# ESP32-S3 register map
Vendor: ESPRESSIF SYSTEMS (SHANGHAI) CO., LTD.; Series: ESP32 S-Series; File version: 22
CPU: Xtensa LX7 r0p0, little endian, no MPU, FPU, 0 interrupt priority bits
Address unit: 32 bits
Registers are 32-bit, read-write, reset 0x0 unless marked. A register's access mark holds for its fields unless they carry their own. Offsets are from the block's base; [hi:lo] are bit positions; {n}, {i} and the like mark numbered series.

## USB_DEVICE — Full-speed USB Serial/JTAG Controller
Base 0x60038000
0x00 EP1 — Endpoint 1 FIFO register
  [7:0] RDWR_BYTE — Write and read byte data to/from UART Tx/Rx FIFO through this field. When USB_DEVICE_SERIAL_IN_EMPTY_INT is set, then user can write data (up to 64 bytes) into UART Tx FIFO. When USB_DEVICE_SERIAL_OUT_RECV_PKT_INT is set, user can check USB_DEVICE_OUT_EP1_WR_ADDR USB_DEVICE_OUT_EP0_RD_ADDR to know how many data is received, then read data from UART Rx FIFO.
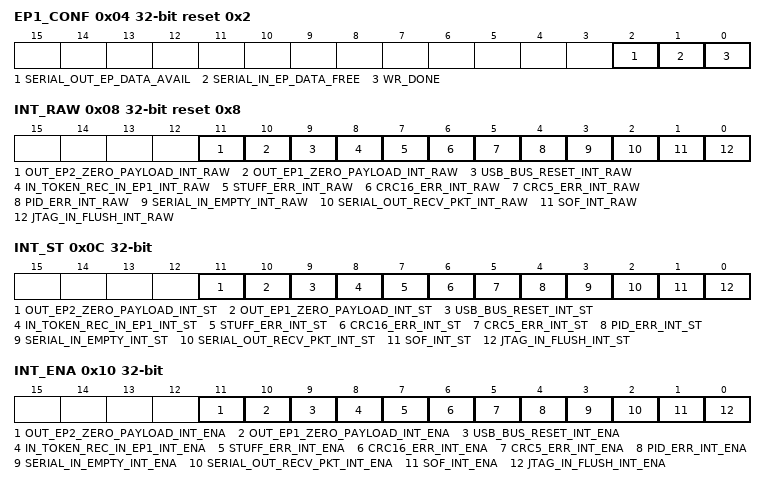
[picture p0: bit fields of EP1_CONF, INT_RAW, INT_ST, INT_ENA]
0x04 EP1_CONF access per field reset 0x2 — Endpoint 1 configure and status register
  [2] SERIAL_OUT_EP_DATA_AVAIL ro — 1'b1: Indicate there is data in UART Rx FIFO.
  [1] SERIAL_IN_EP_DATA_FREE ro — 1'b1: Indicate UART Tx FIFO is not full and can write data into in. After writing USB_DEVICE_WR_DONE, this bit would be 0 until data in UART Tx FIFO is read by USB Host.
  [0] WR_DONE wo — Set this bit to indicate writing byte data to UART Tx FIFO is done.
0x08 INT_RAW reset 0x8 — Raw status interrupt
  [11] OUT_EP2_ZERO_PAYLOAD_INT_RAW — The raw interrupt bit turns to high level when OUT endpoint 2 received packet with zero palyload.
  [10] OUT_EP1_ZERO_PAYLOAD_INT_RAW — The raw interrupt bit turns to high level when OUT endpoint 1 received packet with zero palyload.
  [9] USB_BUS_RESET_INT_RAW — The raw interrupt bit turns to high level when usb bus reset is detected.
  [8] IN_TOKEN_REC_IN_EP1_INT_RAW — The raw interrupt bit turns to high level when IN token for IN endpoint 1 is received.
  [7] STUFF_ERR_INT_RAW — The raw interrupt bit turns to high level when stuff error is detected.
  [6] CRC16_ERR_INT_RAW — The raw interrupt bit turns to high level when CRC16 error is detected.
  [5] CRC5_ERR_INT_RAW — The raw interrupt bit turns to high level when CRC5 error is detected.
  [4] PID_ERR_INT_RAW — The raw interrupt bit turns to high level when pid error is detected.
  [3] SERIAL_IN_EMPTY_INT_RAW — The raw interrupt bit turns to high level when Serial Port IN Endpoint is empty.
  [2] SERIAL_OUT_RECV_PKT_INT_RAW — The raw interrupt bit turns to high level when Serial Port OUT Endpoint received one packet.
  [1] SOF_INT_RAW — The raw interrupt bit turns to high level when SOF frame is received.
  [0] JTAG_IN_FLUSH_INT_RAW — The raw interrupt bit turns to high level when flush cmd is received for IN endpoint 2 of JTAG.
0x0C INT_ST ro — Masked interrupt
  [11] OUT_EP2_ZERO_PAYLOAD_INT_ST — The raw interrupt status bit for the USB_DEVICE_OUT_EP2_ZERO_PAYLOAD_INT interrupt.
  [10] OUT_EP1_ZERO_PAYLOAD_INT_ST — The raw interrupt status bit for the USB_DEVICE_OUT_EP1_ZERO_PAYLOAD_INT interrupt.
  [9] USB_BUS_RESET_INT_ST — The raw interrupt status bit for the USB_DEVICE_USB_BUS_RESET_INT interrupt.
  [8] IN_TOKEN_REC_IN_EP1_INT_ST — The raw interrupt status bit for the USB_DEVICE_IN_TOKEN_REC_IN_EP1_INT interrupt.
  [7] STUFF_ERR_INT_ST — The raw interrupt status bit for the USB_DEVICE_STUFF_ERR_INT interrupt.
  [6] CRC16_ERR_INT_ST — The raw interrupt status bit for the USB_DEVICE_CRC16_ERR_INT interrupt.
  [5] CRC5_ERR_INT_ST — The raw interrupt status bit for the USB_DEVICE_CRC5_ERR_INT interrupt.
  [4] PID_ERR_INT_ST — The raw interrupt status bit for the USB_DEVICE_PID_ERR_INT interrupt.
  [3] SERIAL_IN_EMPTY_INT_ST — The raw interrupt status bit for the USB_DEVICE_SERIAL_IN_EMPTY_INT interrupt.
  [2] SERIAL_OUT_RECV_PKT_INT_ST — The raw interrupt status bit for the USB_DEVICE_SERIAL_OUT_RECV_PKT_INT interrupt.
  [1] SOF_INT_ST — The raw interrupt status bit for the USB_DEVICE_SOF_INT interrupt.
  [0] JTAG_IN_FLUSH_INT_ST — The raw interrupt status bit for the USB_DEVICE_JTAG_IN_FLUSH_INT interrupt.
0x10 INT_ENA — Interrupt enable bits
  [11] OUT_EP2_ZERO_PAYLOAD_INT_ENA — The interrupt enable bit for the USB_DEVICE_OUT_EP2_ZERO_PAYLOAD_INT interrupt.
  [10] OUT_EP1_ZERO_PAYLOAD_INT_ENA — The interrupt enable bit for the USB_DEVICE_OUT_EP1_ZERO_PAYLOAD_INT interrupt.
  [9] USB_BUS_RESET_INT_ENA — The interrupt enable bit for the USB_DEVICE_USB_BUS_RESET_INT interrupt.
  [8] IN_TOKEN_REC_IN_EP1_INT_ENA — The interrupt enable bit for the USB_DEVICE_IN_TOKEN_REC_IN_EP1_INT interrupt.
  [7] STUFF_ERR_INT_ENA — The interrupt enable bit for the USB_DEVICE_STUFF_ERR_INT interrupt.
  [6] CRC16_ERR_INT_ENA — The interrupt enable bit for the USB_DEVICE_CRC16_ERR_INT interrupt.
  [5] CRC5_ERR_INT_ENA — The interrupt enable bit for the USB_DEVICE_CRC5_ERR_INT interrupt.
  [4] PID_ERR_INT_ENA — The interrupt enable bit for the USB_DEVICE_PID_ERR_INT interrupt.
  [3] SERIAL_IN_EMPTY_INT_ENA — The interrupt enable bit for the USB_DEVICE_SERIAL_IN_EMPTY_INT interrupt.
  [2] SERIAL_OUT_RECV_PKT_INT_ENA — The interrupt enable bit for the USB_DEVICE_SERIAL_OUT_RECV_PKT_INT interrupt.
  [1] SOF_INT_ENA — The interrupt enable bit for the USB_DEVICE_SOF_INT interrupt.
  [0] JTAG_IN_FLUSH_INT_ENA — The interrupt enable bit for the USB_DEVICE_JTAG_IN_FLUSH_INT interrupt.
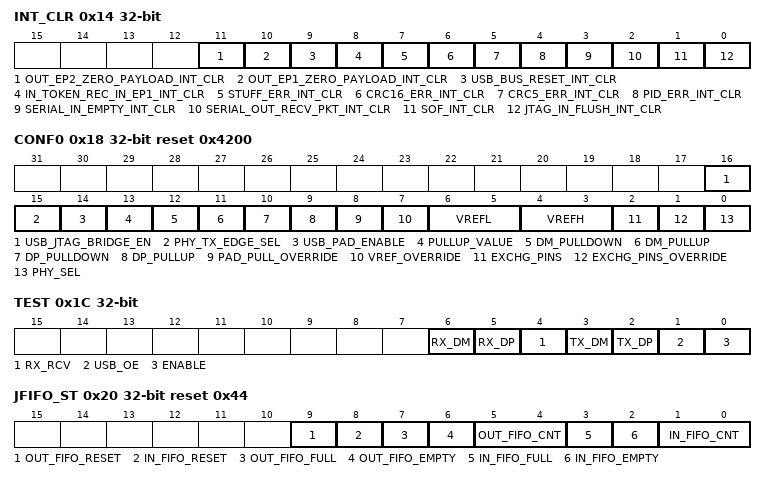
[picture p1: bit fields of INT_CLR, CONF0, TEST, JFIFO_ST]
0x14 INT_CLR wo — Interrupt clear bits
  [11] OUT_EP2_ZERO_PAYLOAD_INT_CLR — Set this bit to clear the USB_DEVICE_OUT_EP2_ZERO_PAYLOAD_INT interrupt.
  [10] OUT_EP1_ZERO_PAYLOAD_INT_CLR — Set this bit to clear the USB_DEVICE_OUT_EP1_ZERO_PAYLOAD_INT interrupt.
  [9] USB_BUS_RESET_INT_CLR — Set this bit to clear the USB_DEVICE_USB_BUS_RESET_INT interrupt.
  [8] IN_TOKEN_REC_IN_EP1_INT_CLR — Set this bit to clear the USB_DEVICE_IN_TOKEN_IN_EP1_INT interrupt.
  [7] STUFF_ERR_INT_CLR — Set this bit to clear the USB_DEVICE_STUFF_ERR_INT interrupt.
  [6] CRC16_ERR_INT_CLR — Set this bit to clear the USB_DEVICE_CRC16_ERR_INT interrupt.
  [5] CRC5_ERR_INT_CLR — Set this bit to clear the USB_DEVICE_CRC5_ERR_INT interrupt.
  [4] PID_ERR_INT_CLR — Set this bit to clear the USB_DEVICE_PID_ERR_INT interrupt.
  [3] SERIAL_IN_EMPTY_INT_CLR — Set this bit to clear the USB_DEVICE_SERIAL_IN_EMPTY_INT interrupt.
  [2] SERIAL_OUT_RECV_PKT_INT_CLR — Set this bit to clear the USB_DEVICE_SERIAL_OUT_RECV_PKT_INT interrupt.
  [1] SOF_INT_CLR — Set this bit to clear the USB_DEVICE_JTAG_SOF_INT interrupt.
  [0] JTAG_IN_FLUSH_INT_CLR — Set this bit to clear the USB_DEVICE_JTAG_IN_FLUSH_INT interrupt.
0x18 CONF0 reset 0x4200 — Configure 0 register
  [16] USB_JTAG_BRIDGE_EN — Set this bit usb_jtag, the connection between usb_jtag and internal JTAG is disconnected, and MTMS, MTDI, MTCK are output through GPIO Matrix, MTDO is input through GPIO Matrix.
  [15] PHY_TX_EDGE_SEL — 0: TX output at clock negedge. 1: Tx output at clock posedge.
  [14] USB_PAD_ENABLE — Enable USB pad function.
  [13] PULLUP_VALUE — Control pull up value.
  [12] DM_PULLDOWN — Control USB D- pull down.
  [11] DM_PULLUP — Control USB D- pull up.
  [10] DP_PULLDOWN — Control USB D+ pull down.
  [9] DP_PULLUP — Control USB D+ pull up.
  [8] PAD_PULL_OVERRIDE — Enable software control USB D+ D- pullup pulldown
  [7] VREF_OVERRIDE — Enable software control input threshold
  [6:5] VREFL — Control single-end input low threshold,0.8V to 1.04V, step 80mV
  [4:3] VREFH — Control single-end input high threshold,1.76V to 2V, step 80mV
  [2] EXCHG_PINS — USB D+ D- exchange
  [1] EXCHG_PINS_OVERRIDE — Enable software control USB D+ D- exchange
  [0] PHY_SEL — Select internal/external PHY
0x1C TEST access per field — USB Internal PHY test register
  [6] RX_DM ro — USB D- rx value in test
  [5] RX_DP ro — USB D+ rx value in test
  [4] RX_RCV ro — USB differential rx value in test
  [3] TX_DM rw — USB D- tx value in test
  [2] TX_DP rw — USB D+ tx value in test
  [1] USB_OE rw — USB pad oen in test
  [0] ENABLE rw — Enable test of the USB pad
0x20 JFIFO_ST access per field reset 0x44 — USB-JTAG FIFO status
  [9] OUT_FIFO_RESET rw — Write 1 to reset JTAG out fifo.
  [8] IN_FIFO_RESET rw — Write 1 to reset JTAG in fifo.
  [7] OUT_FIFO_FULL ro — 1: JTAG out fifo is full.
  [6] OUT_FIFO_EMPTY ro — 1: JTAG out fifo is empty.
  [5:4] OUT_FIFO_CNT ro — JTAT out fifo counter.
  [3] IN_FIFO_FULL ro — 1: JTAG in fifo is full.
  [2] IN_FIFO_EMPTY ro — 1: JTAG in fifo is empty.
  [1:0] IN_FIFO_CNT ro — JTAT in fifo counter.
0x24 FRAM_NUM ro — SOF frame number
  [10:0] SOF_FRAME_INDEX — Frame index of received SOF frame.
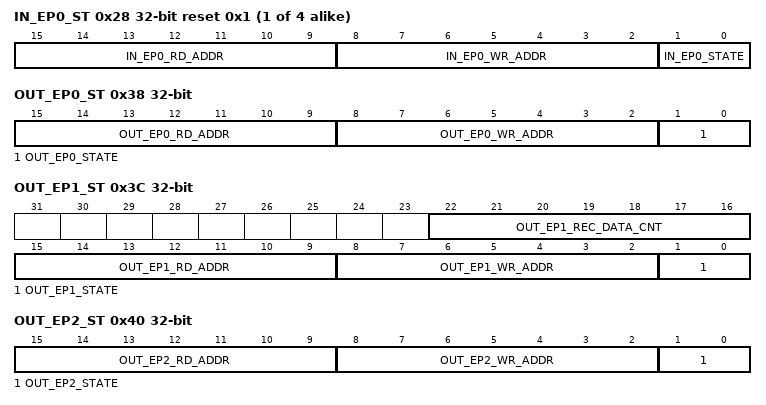
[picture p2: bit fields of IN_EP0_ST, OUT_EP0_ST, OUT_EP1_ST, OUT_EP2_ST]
{0x28+4i} IN_EP{i}_ST ro reset 0x1 (i=0..3) — IN Endpoint {i} status
  [15:9] IN_EP{i}_RD_ADDR — Read data address of IN endpoint {i}.
  [8:2] IN_EP{i}_WR_ADDR — Write data address of IN endpoint {i}.
  [1:0] IN_EP{i}_STATE — State of IN Endpoint {i}.
0x38 OUT_EP0_ST ro — OUT Endpoint 0 status
  [15:9] OUT_EP0_RD_ADDR — Read data address of OUT endpoint 0.
  [8:2] OUT_EP0_WR_ADDR — Write data address of OUT endpoint 0. When USB_DEVICE_SERIAL_OUT_RECV_PKT_INT is detected, there are USB_DEVICE_OUT_EP0_WR_ADDR-2 bytes data in OUT EP0.
  [1:0] OUT_EP0_STATE — State of OUT Endpoint 0.
0x3C OUT_EP1_ST ro — OUT Endpoint 1 status
  [22:16] OUT_EP1_REC_DATA_CNT — Data count in OUT endpoint 1 when one packet is received.
  [15:9] OUT_EP1_RD_ADDR — Read data address of OUT endpoint 1.
  [8:2] OUT_EP1_WR_ADDR — Write data address of OUT endpoint 1. When USB_DEVICE_SERIAL_OUT_RECV_PKT_INT is detected, there are USB_DEVICE_OUT_EP1_WR_ADDR-2 bytes data in OUT EP1.
  [1:0] OUT_EP1_STATE — State of OUT Endpoint 1.
0x40 OUT_EP2_ST ro — OUT Endpoint 2 status
  [15:9] OUT_EP2_RD_ADDR — Read data address of OUT endpoint 2.
  [8:2] OUT_EP2_WR_ADDR — Write data address of OUT endpoint 2. When USB_DEVICE_SERIAL_OUT_RECV_PKT_INT is detected, there are USB_DEVICE_OUT_EP2_WR_ADDR-2 bytes data in OUT EP2.
  [1:0] OUT_EP2_STATE — State of OUT Endpoint 2.
0x44 MISC_CONF — MISC register
  [0] CLK_EN — 1'h1: Force clock on for register. 1'h0: Support clock only when application writes registers.
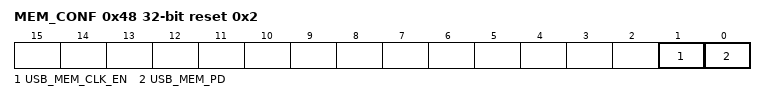
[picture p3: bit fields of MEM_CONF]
0x48 MEM_CONF reset 0x2 — Power control
  [1] USB_MEM_CLK_EN — 1: Force clock on for usb memory.
  [0] USB_MEM_PD — 1: power down usb memory.
0x80 DATE reset 0x2101200 — Version control register
  [31:0] DATE — register version.
